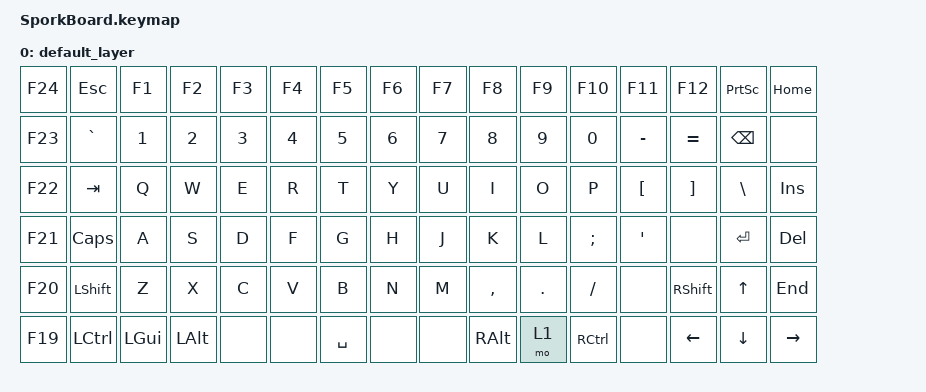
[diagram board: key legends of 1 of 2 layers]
#include <behaviors.dtsi>
#include <dt-bindings/zmk/keys.h>
#include <dt-bindings/zmk/bt.h>


/ {


behaviors {
    mo: momentary_layer {
        compatible = "zmk,behavior-momentary-layer";
        label = "MOMENTARY_LAYER";
    };
    kp: key_press {
        compatible = "zmk,behavior-key-press";
        label = "KEY_PRESS";
    };
    // Add these:
    trans: transparent {
        compatible = "zmk,behavior-transparent";
        label = "TRANSPARENT";
    };
    bt: bluetooth_select {
        // Check ZMK source for exact compatible string if this doesn't work
        compatible = "zmk,behavior-bluetooth-select"; 
        label = "BLUETOOTH_SELECT";
    };
    bt_clear: bluetooth_clear {
        // Check ZMK source for exact compatible string if this doesn't work
        compatible = "zmk,behavior-bluetooth-clear"; 
        label = "BLUETOOTH_CLEAR";
    };
};

  keymap {
    compatible = "zmk,keymap";

    default_layer {
        // ------------------------------------------------------------------------------------------------
        // | F24 | ESC | F1  | F2  | F3  | F4  | F5  | F6  | F7  | F9  | F9  | F10 | F11 | F12 |PSCRN|HOME
        // | F23 |GRAVE|  1  |  2  |  3  |  4  |  5  |  6  |  7  |  8  |  9  |  0  |  -  |  =  |   BSPC   |
        // | F22 | TAB   |  Q  |  W  |  E  |  R  |  T  |  Y  |  U  |  I  |  O  |  P  |  [  |  ]  |   \    | INS |
        // | F21 | CAPS   |  A  |  S  |  D  |  F  |  G  |  H  |  J  |  K  |  L  |  ;  |  '  |    ENTER    | DEL |
        // | F20 |  SHIFT   |  Z  |  X  |  C  |  V  |  B  |  N  |  M  |  ,  |  .  |  /  |   SHIFT   | UP  | END |
        // | F19 |  CTL  |  WIN  |  ALT  |             SPACE                | ALT |  1  |RCTRL| LEFT| DOWN|RIGHT|
        // ------------------------------------------------------------------------------------------------
      bindings = <
        &kp F24 &kp ESC   &kp F1    &kp F2    &kp F3  &kp F4 &kp F5     &kp F6  &kp F7  &kp F8    &kp F9    &kp F10   &kp F11    &kp F12    &kp PSCRN  &kp HOME
        &kp F23 &kp GRAVE &kp N1    &kp N2    &kp N3  &kp N4 &kp N5     &kp N6  &kp N7  &kp N8    &kp N9    &kp N0    &kp MINUS  &kp EQUAL  &kp BSPC   &none
        &kp F22 &kp TAB   &kp Q     &kp W     &kp E   &kp R  &kp T      &kp Y   &kp U   &kp I     &kp  O    &kp  P    &kp LBKT   &kp RBKT   &kp BSLH   &kp INS
        &kp F21 &kp CLCK  &kp A     &kp S     &kp D   &kp F  &kp G      &kp H   &kp J   &kp K     &kp  L    &kp SEMI  &kp SQT    &none      &kp RET    &kp DEL
        &kp F20 &kp LSHFT &kp Z     &kp X     &kp C   &kp V  &kp B      &kp N   &kp M   &kp COMMA &kp DOT   &kp FSLH  &none      &kp RSHFT  &kp UP     &kp END
        &kp F19 &kp LCTRL &kp LGUI  &kp LALT  &none   &none  &kp SPACE  &none   &none   &kp RALT  &mo 1     &kp RCTRL &none      &kp LEFT   &kp DOWN   &kp RIGHT
      >;
    };
    raise_layer {
        // ------------------------------------------------------------------------------------------------
        // | F24 | ESC | F1  | F2  | F3  | F4  | F5  | F6  | F7  | F9  | F9  | F10 | F11 | F12 |PSCRN|HOME
        // | F23 | TILDE |  BT1  |  BT2  |  BT3  |  BT4  |  BT5  |  ^  |  &  |  *  |  (  |  )  |  _  |  +  |   BTCLR   
        // | F22 | TAB   |  Q  |  W  |  E  |  R  |  T  |  Y  |  U  |  I  |  O  |  P  |  {  |  }  |   |    | INS |
        // | F21 | CAPS   |  A  |  S  |  D  |  F  |  G  |  H  |  J  |  K  |  L  |  :  |  "  |    ENTER    | PGUP|
        // | F20 |  SHIFT   |  Z  |  X  |  C  |  V  |  B  |  N  |  M  |  <  |  >  |  ?  |   SHIFT   | UP  | PGDN|
        // | F19 |  CTL  |  WIN  |  ALT  |             SPACE                | ALT |  1  |RCTRL| LEFT| DOWN|RIGHT|
        // ------------------------------------------------------------------------------------------------
    bindings = <
        &trans &trans &trans &trans &trans &trans &trans &trans &trans &trans &trans &trans &trans &trans &trans &trans
        &trans &trans &bt BT_SEL 1 &bt BT_SEL 2 &bt BT_SEL 3 &trans &trans &trans &trans &trans &trans &trans &trans &bt BT_CLR
        &trans &trans &trans &trans &trans &trans &trans &trans &trans &trans &trans &trans &trans &trans &trans &trans
        &trans &trans &trans &trans &trans &trans &trans &trans &trans &trans &trans &trans &trans &trans &trans &trans
        &trans &trans &trans &trans &trans &trans &trans &trans &trans &trans &trans &trans &trans &trans &trans &trans
        &trans &trans &trans &trans &trans &trans &trans &trans &trans &trans &trans &trans &trans &trans &trans &trans
      >;
    };
  };
};
